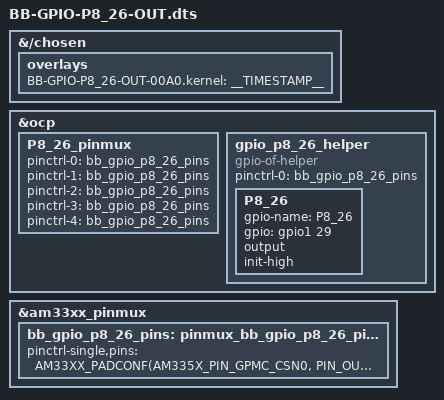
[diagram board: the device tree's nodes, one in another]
// SPDX-License-Identifier: GPL-2.0-only
/*
 * Copyright (C) 2025 Custom
 * Virtual cape for GPIO output on connector pin P8.26
 */
/dts-v1/;
/plugin/;
#include <dt-bindings/gpio/gpio.h>
#include <dt-bindings/pinctrl/am33xx.h>
#include <dt-bindings/interrupt-controller/irq.h>

/*
 * Helper to show loaded overlays under: /proc/device-tree/chosen/overlays/
 */
&{/chosen} {
        overlays {
                BB-GPIO-P8_26-OUT-00A0.kernel = __TIMESTAMP__;
        };
};

/*
 * Override the default pinmux state for P8_26
 */
&ocp {
        P8_26_pinmux {
                /* Keep pinmux helper enabled but override the state */
                pinctrl-names = "default", "gpio", "gpio_pu", "gpio_pd", "gpio_out";
                pinctrl-0 = <&bb_gpio_p8_26_pins>;  /* default state */
                pinctrl-1 = <&bb_gpio_p8_26_pins>;  /* gpio state */
                pinctrl-2 = <&bb_gpio_p8_26_pins>;  /* gpio_pu state */
                pinctrl-3 = <&bb_gpio_p8_26_pins>;  /* gpio_pd state */
                pinctrl-4 = <&bb_gpio_p8_26_pins>;  /* gpio_out state */
        };
};

&am33xx_pinmux {
        bb_gpio_p8_26_pins: pinmux_bb_gpio_p8_26_pins {
                pinctrl-single,pins = <
                        AM33XX_PADCONF(AM335X_PIN_GPMC_CSN0, PIN_OUTPUT, MUX_MODE7)  /* P8_26 (U18) gpmc_csn0.gpio1_29 */
                >;
        };
};

&ocp {
        gpio_p8_26_helper: gpio_p8_26_helper {
                compatible = "gpio-of-helper";
                status = "okay";
                pinctrl-names = "default";
                pinctrl-0 = <&bb_gpio_p8_26_pins>;

                P8_26 {
                        gpio-name = "P8_26";
                        gpio = <&gpio1 29 GPIO_ACTIVE_HIGH>;
                        output;
                        init-high;
                };
        };
};
